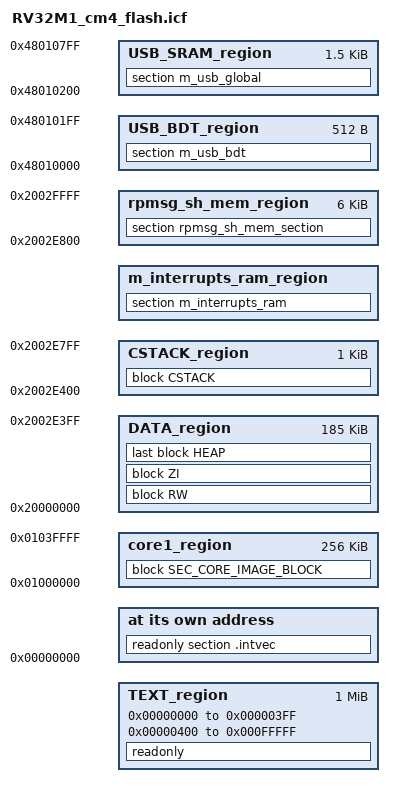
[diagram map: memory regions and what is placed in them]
/*
** ###################################################################
**     Processors:          RV32M1_cm4
**                          RV32M1_cm4
**
**     Compiler:            IAR ANSI C/C++ Compiler for ARM
**     Reference manual:    RV32M1 Series Reference Manual, Rev. 1 , 8/10/2018
**     Version:             rev. 1.0, 2018-10-02
**     Build:               b171115
**
**     Abstract:
**         Linker file for the IAR ANSI C/C++ Compiler for ARM
**
**     Copyright 2016 Freescale Semiconductor, Inc.
**     Copyright 2016-2017 NXP
**     All rights reserved.
**     
**     SPDX-License-Identifier: BSD-3-Clause
**
**     http:                 www.nxp.com
**     mail:                 support@nxp.com
**
** ###################################################################
*/

define symbol __ram_vector_table_size__ =  isdefinedsymbol(__ram_vector_table__) ? 0x00000400 : 0;
define symbol __ram_vector_table_offset__ =  isdefinedsymbol(__ram_vector_table__) ? 0x000003FF : 0;

define symbol m_interrupts_start       = 0x00000000;
define symbol m_interrupts_end         = 0x000003FF;

define symbol m_text_start             = 0x00000400;
define symbol m_text_end               = 0x000FFFFF;

define symbol m_interrupts_ram_start   = 0x08000000;
define symbol m_interrupts_ram_end     = 0x08000000 + __ram_vector_table_offset__;

define exported symbol core1_image_start     = 0x01000000;
define exported symbol core1_image_end       = 0x0103FFFF;

if (isdefinedsymbol(__use_shmem__)) {
  define symbol m_data_start                   = 0x20000000;
  define symbol m_data_end                     = 0x2002E7FF;
  define exported symbol rpmsg_sh_mem_start    = 0x2002E800;
  define exported symbol rpmsg_sh_mem_end      = 0x2002FFFF;
} else {
  define symbol m_data_start           = 0x20000000;
  define symbol m_data_end             = 0x2002FFFF;
}

define symbol m_usb_sram_start         = 0x48010000;
define symbol m_usb_sram_end           = 0x480107FF;

/* USB BDT size */
define symbol usb_bdt_size             = 0x200;

/* Sizes */
if (isdefinedsymbol(__stack_size__)) {
  define symbol __size_cstack__        = __stack_size__;
} else {
  define symbol __size_cstack__        = 0x0400;
}

if (isdefinedsymbol(__heap_size__)) {
  define symbol __size_heap__          = __heap_size__;
} else {
  define symbol __size_heap__          = 0x0400;
}

define exported symbol __VECTOR_TABLE  = m_interrupts_start;
define exported symbol __VECTOR_RAM    = isdefinedsymbol(__ram_vector_table__) ? m_interrupts_ram_start : m_interrupts_start;
define exported symbol __RAM_VECTOR_TABLE_SIZE = __ram_vector_table_size__;

define memory mem with size = 4G;
define region TEXT_region = mem:[from m_interrupts_start to m_interrupts_end]
                          | mem:[from m_text_start to m_text_end];
define region DATA_region = mem:[from m_data_start to m_data_end-__size_cstack__];
define region CSTACK_region = mem:[from m_data_end-__size_cstack__+1 to m_data_end];
define region m_interrupts_ram_region = mem:[from m_interrupts_ram_start to m_interrupts_ram_end];
if (isdefinedsymbol(__use_shmem__)) {
  define region rpmsg_sh_mem_region     = mem:[from rpmsg_sh_mem_start to rpmsg_sh_mem_end];
}

define block CSTACK    with alignment = 8, size = __size_cstack__   { };
define block HEAP      with alignment = 8, size = __size_heap__     { };
define block RW        { readwrite };
define block ZI        { zi };

define region core1_region = mem:[from core1_image_start to core1_image_end];
define block SEC_CORE_IMAGE_BLOCK          { section  __sec_core };

/* regions for USB */
define region USB_BDT_region = mem:[from m_usb_sram_start to m_usb_sram_start + usb_bdt_size - 1];
define region USB_SRAM_region = mem:[from m_usb_sram_start + usb_bdt_size to m_usb_sram_end];
place in USB_BDT_region                     { section m_usb_bdt };
place in USB_SRAM_region                    { section m_usb_global };

initialize by copy { readwrite, section .textrw };
do not initialize  { section .noinit, section m_usb_bdt, section m_usb_global };
if (isdefinedsymbol(__use_shmem__)) {
  do not initialize  { section rpmsg_sh_mem_section };
}

place at address mem: m_interrupts_start    { readonly section .intvec };
place in TEXT_region                        { readonly };
place in DATA_region                        { block RW };
place in DATA_region                        { block ZI };
place in DATA_region                        { last block HEAP };
place in CSTACK_region                      { block CSTACK };
place in m_interrupts_ram_region            { section m_interrupts_ram };
if (isdefinedsymbol(__use_shmem__)) {
  place in rpmsg_sh_mem_region                { section rpmsg_sh_mem_section };
}
place in core1_region                       { block SEC_CORE_IMAGE_BLOCK };

